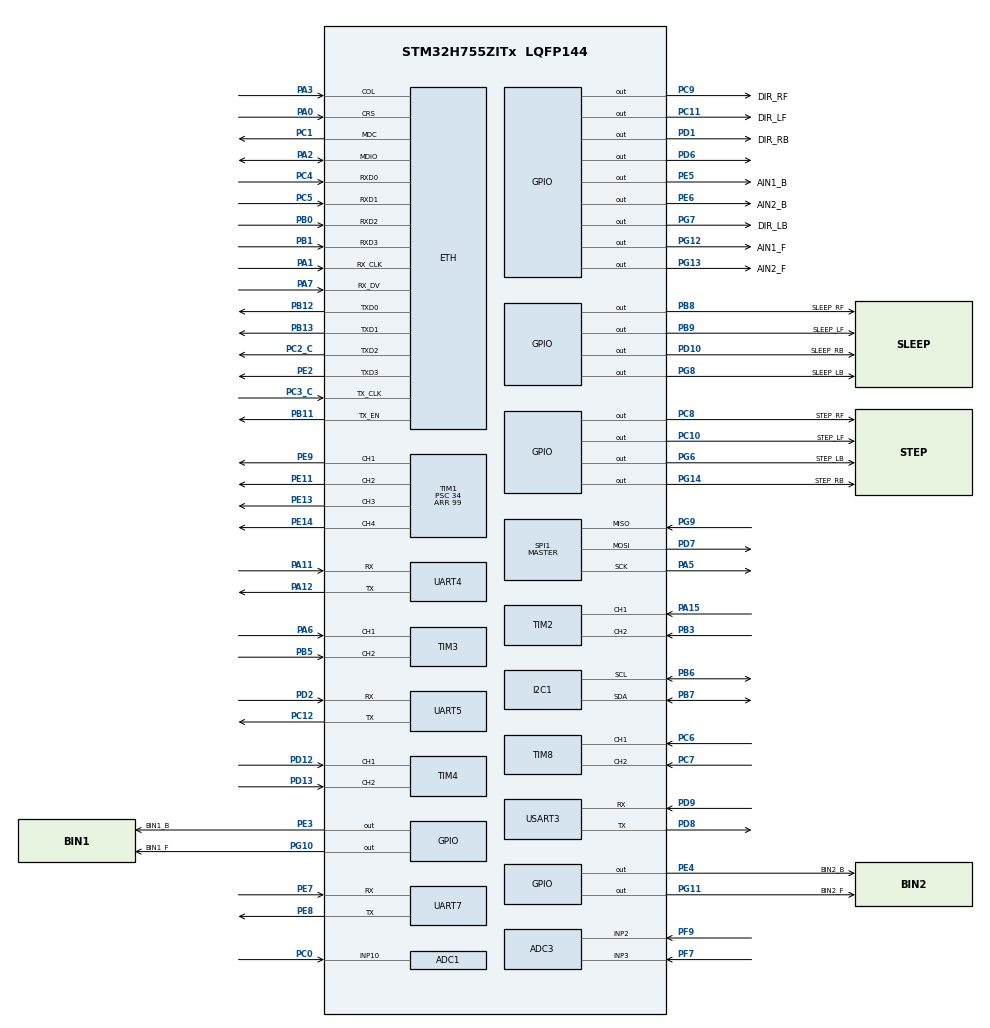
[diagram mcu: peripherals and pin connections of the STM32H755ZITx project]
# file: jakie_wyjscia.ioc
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ADC1.Channel-0\#ChannelRegularConversion=ADC_CHANNEL_10
ADC1.ClockPrescaler=ADC_CLOCK_ASYNC_DIV4
ADC1.NbrOfConversionFlag=1
ADC1.OffsetNumber-0\#ChannelRegularConversion=ADC_OFFSET_NONE
ADC1.OffsetSignedSaturation-0\#ChannelRegularConversion=DISABLE
ADC1.Rank-0\#ChannelRegularConversion=1
ADC1.SamplingTime-0\#ChannelRegularConversion=ADC_SAMPLETIME_1CYCLE_5
ADC1.master=1
ADC3.Channel-0\#ChannelRegularConversion=ADC_CHANNEL_2
ADC3.ClockPrescaler=ADC_CLOCK_ASYNC_DIV4
ADC3.NbrOfConversionFlag=1
ADC3.OffsetNumber-0\#ChannelRegularConversion=ADC_OFFSET_NONE
ADC3.OffsetSignedSaturation-0\#ChannelRegularConversion=DISABLE
ADC3.Rank-0\#ChannelRegularConversion=1
ADC3.SamplingTime-0\#ChannelRegularConversion=ADC_SAMPLETIME_1CYCLE_5
CORTEX_M7.default_mode_Activation=1
CortexM4.IPs=BDMA,CORTEX_M4\:I,DMA,FATFS_M4\:I,FREERTOS_M4\:I,GPIO,IWDG2\:I,MDMA,NVIC2\:I,OPENAMP_M4\:I,PDM2PCM_M4\:I,PWR,RCC,RESMGR_UTILITY,SYS_M4\:I,USB_DEVICE_M4\:I,USB_HOST_M4\:I,VREFBUF,WWDG2\:I
CortexM7.IPs=BDMA\:I,CORTEX_M7\:I,DMA\:I,FATFS_M7\:I,FREERTOS_M7\:I,GPIO\:I,IWDG1\:I,MDMA\:I,NVIC1\:I,OPENAMP_M7\:I,PDM2PCM_M7\:I,PWR\:I,RCC\:I,RESMGR_UTILITY\:I,SYS\:I,USB_DEVICE_M7\:I,USB_HOST_M7\:I,VREFBUF\:I,WWDG1\:I,MEMORYMAP\:I,ETH\:I,LWIP\:I,TIM1\:I,TIM2\:I,TIM3\:I,TIM4\:I,TIM8\:I,ADC3\:I,ADC1\:I,SPI1\:I,UART4\:I,DAC1\:I,ADC2\:I,TIM6\:I,TIM7\:I,UART7\:I,I2C1\:I,TIM13\:I,TIM14\:I,UART5\:I,USART3\:I,TIM15\:I
CortexM7.Pins=PE3,PE4,PE5,PE6,PD10,PG6,PG7,PG8,PC8,PC9,PC10,PC11,PD1,PD6,PG10,PG11,PG12,PG13,PG14,PB8,PB9
ETH.MediaInterface=HAL_ETH_MII_MODE
I2C1.Timing=0x00707CBB
LWIP.Version=v2.1.2_Cube
Mcu.Family=STM32H7
Mcu.Name=STM32H755ZITx
Mcu.Package=LQFP144
NVIC1.PriorityGroup=NVIC_PRIORITYGROUP_4
NVIC1.TIM15_IRQn=true\:0\:0\:false\:false\:true\:true\:true\:true
NVIC1.TIM2_IRQn=true\:0\:0\:false\:false\:true\:true\:true\:true
NVIC1.TIM6_DAC_IRQn=true\:0\:0\:false\:false\:true\:true\:true\:true
NVIC1.TIM7_IRQn=true\:0\:0\:false\:false\:true\:true\:true\:true
NVIC1.TIM8_TRG_COM_TIM14_IRQn=true\:0\:0\:false\:false\:true\:true\:true\:true
NVIC1.TIM8_UP_TIM13_IRQn=true\:0\:0\:false\:false\:true\:true\:true\:true
NVIC1.USART3_IRQn=true\:0\:0\:false\:false\:true\:true\:true\:true
NVIC2.PriorityGroup=NVIC_PRIORITYGROUP_4
PA0.Mode=MII
PA0.PinAttribute=CortexM7
PA0.Signal=ETH_CRS
PA1.Mode=MII
PA1.PinAttribute=CortexM7
PA1.Signal=ETH_RX_CLK
PA11.Mode=Asynchronous
PA11.PinAttribute=CortexM7
PA11.Signal=UART4_RX
PA12.Mode=Asynchronous
PA12.PinAttribute=CortexM7
PA12.Signal=UART4_TX
PA15\ (JTDI).PinAttribute=CortexM7
PA15\ (JTDI).Signal=S_TIM2_CH1_ETR
PA2.Mode=MII
PA2.PinAttribute=CortexM7
PA2.Signal=ETH_MDIO
PA3.Mode=MII
PA3.PinAttribute=CortexM7
PA3.Signal=ETH_COL
PA5.Mode=Full_Duplex_Master
PA5.PinAttribute=CortexM7
PA5.Signal=SPI1_SCK
PA6.PinAttribute=CortexM7
PA6.Signal=S_TIM3_CH1
PA7.Mode=MII
PA7.PinAttribute=CortexM7
PA7.Signal=ETH_RX_DV
PB0.Mode=MII
PB0.PinAttribute=CortexM7
PB0.Signal=ETH_RXD2
PB1.Mode=MII
PB1.PinAttribute=CortexM7
PB1.Signal=ETH_RXD3
PB11.Mode=MII
PB11.PinAttribute=CortexM7
PB11.Signal=ETH_TX_EN
PB12.Mode=MII
PB12.PinAttribute=CortexM7
PB12.Signal=ETH_TXD0
PB13.Mode=MII
PB13.PinAttribute=CortexM7
PB13.Signal=ETH_TXD1
PB3\ (JTDO/TRACESWO).PinAttribute=CortexM7
PB3\ (JTDO/TRACESWO).Signal=S_TIM2_CH2
PB5.PinAttribute=CortexM7
PB5.Signal=S_TIM3_CH2
PB6.Mode=I2C
PB6.PinAttribute=CortexM7
PB6.Signal=I2C1_SCL
PB7.Mode=I2C
PB7.PinAttribute=CortexM7
PB7.Signal=I2C1_SDA
PB8.GPIO_FM8=__NULL
PB8.GPIO_Label=SLEEP_RF
PB8.PinAttribute=CortexM7
PB8.Signal=GPIO_Output
PB9.GPIO_FM9=__NULL
PB9.GPIO_Label=SLEEP_LF
PB9.PinAttribute=CortexM7
PB9.Signal=GPIO_Output
PC0.PinAttribute=CortexM7
PC0.Signal=ADCx_INP10
PC1.Mode=MII
PC1.PinAttribute=CortexM7
PC1.Signal=ETH_MDC
PC10.GPIO_Label=STEP_LF
PC10.PinAttribute=CortexM7
PC10.Signal=GPIO_Output
PC11.GPIO_Label=DIR_LF
PC11.PinAttribute=CortexM7
PC11.Signal=GPIO_Output
PC12.Mode=Asynchronous
PC12.PinAttribute=CortexM7
PC12.Signal=UART5_TX
PC2_C.Mode=MII
PC2_C.PinAttribute=CortexM7
PC2_C.Signal=ETH_TXD2
PC3_C.Mode=MII
PC3_C.PinAttribute=CortexM7
PC3_C.Signal=ETH_TX_CLK
PC4.Mode=MII
PC4.PinAttribute=CortexM7
PC4.Signal=ETH_RXD0
PC5.Mode=MII
PC5.PinAttribute=CortexM7
PC5.Signal=ETH_RXD1
PC6.PinAttribute=CortexM7
PC6.Signal=S_TIM8_CH1
PC7.PinAttribute=CortexM7
PC7.Signal=S_TIM8_CH2
PC8.GPIO_Label=STEP_RF
PC8.PinAttribute=CortexM7
PC8.Signal=GPIO_Output
PC9.GPIO_Label=DIR_RF
PC9.PinAttribute=CortexM7
PC9.Signal=GPIO_Output
PD1.GPIO_Label=DIR_RB
PD1.PinAttribute=CortexM7
PD1.Signal=GPIO_Output
PD10.GPIO_Label=SLEEP_RB
PD10.PinAttribute=CortexM7
PD10.Signal=GPIO_Output
PD12.PinAttribute=CortexM7
PD12.Signal=S_TIM4_CH1
PD13.PinAttribute=CortexM7
PD13.Signal=S_TIM4_CH2
PD2.Mode=Asynchronous
PD2.PinAttribute=CortexM7
PD2.Signal=UART5_RX
PD6.PinAttribute=CortexM7
PD6.Signal=GPIO_Output
PD7.Mode=Full_Duplex_Master
PD7.PinAttribute=CortexM7
PD7.Signal=SPI1_MOSI
PD8.Mode=Asynchronous
PD8.PinAttribute=CortexM7
PD8.Signal=USART3_TX
PD9.Mode=Asynchronous
PD9.PinAttribute=CortexM7
PD9.Signal=USART3_RX
PE11.PinAttribute=CortexM7
PE11.Signal=S_TIM1_CH2
PE13.PinAttribute=CortexM7
PE13.Signal=S_TIM1_CH3
PE14.PinAttribute=CortexM7
PE14.Signal=S_TIM1_CH4
PE2.Mode=MII
PE2.PinAttribute=CortexM7
PE2.Signal=ETH_TXD3
PE3.GPIO_Label=BIN1_B
PE3.PinAttribute=CortexM7
PE3.Signal=GPIO_Output
PE4.GPIO_Label=BIN2_B
PE4.PinAttribute=CortexM7
PE4.Signal=GPIO_Output
PE5.GPIO_Label=AIN1_B
PE5.PinAttribute=CortexM7
PE5.Signal=GPIO_Output
PE6.GPIO_Label=AIN2_B
PE6.PinAttribute=CortexM7
PE6.Signal=GPIO_Output
PE7.Mode=Asynchronous
PE7.PinAttribute=CortexM7
PE7.Signal=UART7_RX
PE8.Mode=Asynchronous
PE8.PinAttribute=CortexM7
PE8.Signal=UART7_TX
PE9.PinAttribute=CortexM7
PE9.Signal=S_TIM1_CH1
PF7.Mode=IN3-Single-Ended
PF7.PinAttribute=CortexM7
PF7.Signal=ADC3_INP3
PF9.Mode=IN2-Single-Ended
PF9.PinAttribute=CortexM7
PF9.Signal=ADC3_INP2
PG10.GPIO_Label=BIN1_F
PG10.PinAttribute=CortexM7
PG10.Signal=GPIO_Output
PG11.GPIO_Label=BIN2_F
PG11.PinAttribute=CortexM7
PG11.Signal=GPIO_Output
PG12.GPIO_Label=AIN1_F
PG12.PinAttribute=CortexM7
PG12.Signal=GPIO_Output
PG13.GPIO_Label=AIN2_F
PG13.PinAttribute=CortexM7
PG13.Signal=GPIO_Output
PG14.GPIO_Label=STEP_RB
PG14.PinAttribute=CortexM7
PG14.Signal=GPIO_Output
PG6.GPIO_Label=STEP_LB
PG6.PinAttribute=CortexM7
PG6.Signal=GPIO_Output
PG7.GPIO_Label=DIR_LB
PG7.PinAttribute=CortexM7
PG7.Signal=GPIO_Output
PG8.GPIO_Label=SLEEP_LB
PG8.PinAttribute=CortexM7
PG8.Signal=GPIO_Output
PG9.Mode=Full_Duplex_Master
PG9.PinAttribute=CortexM7
PG9.Signal=SPI1_MISO
ProjectManager.HeapSize=M4-0x200,M7-0x200
ProjectManager.StackSize=M4-0x400,M7-0x400
ProjectManager.TargetToolchain=STM32CubeIDE
RCC.ADCFreq_Value=72000000
RCC.APB1Freq_Value=32000000
RCC.APB2Freq_Value=32000000
RCC.APB3Freq_Value=32000000
RCC.APB4Freq_Value=32000000
RCC.CortexFreq_Value=128000000
RCC.D1PPRE=RCC_APB3_DIV2
RCC.D2PPRE1=RCC_APB1_DIV2
RCC.D2PPRE2=RCC_APB2_DIV2
RCC.D3PPRE=RCC_APB4_DIV2
RCC.DIVM1=4
RCC.DIVM2=4
RCC.DIVN1=16
RCC.DIVN2=9
RCC.DIVQ1=3
RCC.FLatency-AdvancedSettings=FLASH_LATENCY_0
RCC.HCLKFreq_Value=64000000
RCC.HPRE=RCC_HCLK_DIV2
RCC.PLL1_VCI_Range-AdvancedSettings=RCC_PLL1VCIRANGE_0
RCC.PLL2FRACN=0
RCC.PLL2_VCI_Range-AdvancedSettings=RCC_PLL2VCIRANGE_0
RCC.PLL2_VCO_SEL-AdvancedSettings=RCC_PLL2VCOMEDIUM
RCC.PLL3FRACN=0
RCC.PLL3_VCI_Range-AdvancedSettings=RCC_PLL3VCIRANGE_0
RCC.PLL3_VCO_SEL-AdvancedSettings=RCC_PLL3VCOMEDIUM
RCC.PLLFRACN=0
RCC.SYSCLKFreq_VALUE=128000000
RCC.SYSCLKSource=RCC_SYSCLKSOURCE_PLLCLK
RCC.USBFreq_Value=85333333.33333333
SH.ADCx_INP10.0=ADC1_INP10,IN10-Single-Ended
SH.S_TIM1_CH1.0=TIM1_CH1,PWM Generation1 CH1
SH.S_TIM1_CH2.0=TIM1_CH2,PWM Generation2 CH2
SH.S_TIM1_CH3.0=TIM1_CH3,PWM Generation3 CH3
SH.S_TIM1_CH4.0=TIM1_CH4,PWM Generation4 CH4
SH.S_TIM2_CH1_ETR.0=TIM2_CH1,Encoder_Interface
SH.S_TIM2_CH2.0=TIM2_CH2,Encoder_Interface
SH.S_TIM3_CH1.0=TIM3_CH1,Encoder_Interface
SH.S_TIM3_CH2.0=TIM3_CH2,Encoder_Interface
SH.S_TIM4_CH1.0=TIM4_CH1,Encoder_Interface
SH.S_TIM4_CH2.0=TIM4_CH2,Encoder_Interface
SH.S_TIM8_CH1.0=TIM8_CH1,Encoder_Interface
SH.S_TIM8_CH2.0=TIM8_CH2,Encoder_Interface
SPI1.BaudRatePrescaler=SPI_BAUDRATEPRESCALER_2
SPI1.CalculateBaudRate=42.666664 MBits/s
SPI1.Direction=SPI_DIRECTION_2LINES
SPI1.Mode=SPI_MODE_MASTER
SPI1.VirtualType=VM_MASTER
SYS.userName=SYS_M7
TIM1.Channel-PWM\ Generation1\ CH1=TIM_CHANNEL_1
TIM1.Channel-PWM\ Generation2\ CH2=TIM_CHANNEL_2
TIM1.Channel-PWM\ Generation3\ CH3=TIM_CHANNEL_3
TIM1.Channel-PWM\ Generation4\ CH4=TIM_CHANNEL_4
TIM1.Period=99
TIM1.Prescaler=34
TIM13.Period=99
TIM13.Prescaler=6399
TIM14.Period=999
TIM14.Prescaler=39
TIM15.Period=999
TIM15.Prescaler=39
TIM2.EncoderMode=TIM_ENCODERMODE_TI12
TIM3.EncoderMode=TIM_ENCODERMODE_TI12
TIM4.EncoderMode=TIM_ENCODERMODE_TI12
TIM6.Period=999
TIM6.Prescaler=39
TIM7.Period=999
TIM7.Prescaler=39
TIM8.EncoderMode=TIM_ENCODERMODE_TI12
USART3.VirtualMode-Asynchronous=VM_ASYNC
VP_LWIP_VS_Enabled.Mode=Enabled
VP_MEMORYMAP_VS_MEMORYMAP.Mode=CurAppReg
VP_SYS_M4_VS_Systick.Mode=SysTick
VP_TIM13_VS_ClockSourceINT.Mode=Enable_Timer
VP_TIM14_VS_ClockSourceINT.Mode=Enable_Timer
VP_TIM15_VS_ClockSourceINT.Mode=Internal
VP_TIM6_VS_ClockSourceINT.Mode=Enable_Timer
VP_TIM7_VS_ClockSourceINT.Mode=Enable_Timer
board=custom

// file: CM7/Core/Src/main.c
/* USER CODE BEGIN Header */
/**
  ******************************************************************************
  * @file           : main.c
  * @brief          : Main program body
  ******************************************************************************
  * @attention
  *
  * Copyright (c) 2026 STMicroelectronics.
  * All rights reserved.
  *
  * This software is licensed under terms that can be found in the LICENSE file
  * in the root directory of this software component.
  * If no LICENSE file comes with this software, it is provided AS-IS.
  *
  ******************************************************************************
  */
/* USER CODE END Header */
#include "main.h"
#include "lwip.h"

/* USER CODE BEGIN Includes */
#include "motor_control.h"
#include "PI.h"
#include <stdbool.h>
#include <stdio.h>
#include <string.h>
#include <math.h>
/* USER CODE END Includes */

/* USER CODE BEGIN PD */

#ifndef HSEM_ID_0
#define HSEM_ID_0 (0U) /* HW semaphore 0*/
#endif

/* USER CODE END PD */

ADC_HandleTypeDef hadc1;
ADC_HandleTypeDef hadc3;

I2C_HandleTypeDef hi2c1;

SPI_HandleTypeDef hspi1;

TIM_HandleTypeDef htim1;
TIM_HandleTypeDef htim2;
TIM_HandleTypeDef htim3;
TIM_HandleTypeDef htim4;
TIM_HandleTypeDef htim6;
TIM_HandleTypeDef htim7;
TIM_HandleTypeDef htim8;
TIM_HandleTypeDef htim13;
TIM_HandleTypeDef htim14;
TIM_HandleTypeDef htim15;

UART_HandleTypeDef huart4;
UART_HandleTypeDef huart5;
UART_HandleTypeDef huart7;
UART_HandleTypeDef huart3;

/* USER CODE BEGIN PV */
uint8_t rx_byte;		/* bajt z USART3 (przerwanie RX) */
char rx_buffer[50];		/* składana komenda UART aż do '\n' */
uint8_t rx_index = 0;

/* Flagi silników krokowych (1 = dany A4988 ma być aktywny przy forward/backward). */
volatile uint8_t fright = 0, fleft = 0, bright = 0, bleft = 0, stop = 0, forward = 0, backward = 0;
volatile int Rvel = 0, Lvel = 0;	/* zadanie z UART: lspeed/rspeed w % */
volatile uint16_t steps_fright = 0, steps_bright = 0, steps_fleft = 0, steps_bleft = 0;

DC_str right_front, left_front, right_back, left_back;

int Kp = 14;
int Ki = 30;
int32_t MAX_SPEED_RPM = 200;

float P = 0;
volatile uint32_t raw_adc_val1 = 0;
volatile uint32_t raw_adc_val3 = 0;
volatile float PomiarADC;	/* prąd z przetwornika LTS (skalowanie w pętli głównej) */

/* USER CODE END PV */

void SystemClock_Config(void);
void PeriphCommonClock_Config(void);
static void MPU_Config(void);
static void MX_GPIO_Init(void);
static void MX_ADC1_Init(void);
static void MX_ADC3_Init(void);
static void MX_SPI1_Init(void);
static void MX_TIM1_Init(void);
static void MX_TIM2_Init(void);
static void MX_TIM3_Init(void);
static void MX_TIM4_Init(void);
static void MX_TIM8_Init(void);
static void MX_UART4_Init(void);
static void MX_TIM6_Init(void);
static void MX_TIM7_Init(void);
static void MX_UART7_Init(void);
static void MX_I2C1_Init(void);
static void MX_TIM13_Init(void);
static void MX_TIM14_Init(void);
static void MX_UART5_Init(void);
static void MX_USART3_UART_Init(void);
static void MX_TIM15_Init(void);

/* USER CODE BEGIN 0 */
void DC_str_init(DC_str *m, TIM_HandleTypeDef *tim, int8_t d, int32_t max)
{
	m->timer = tim;
	m->pulse_count = 0;
	m->actual_speed = 0;
	m->d = d;			/* znak enkodera — lewa/prawa oś mogą być lustrzane */
	m->max_speed = max;
	m->target_speed = 0;
	m->error_sum = 0;
	m->last_output = 0;
	m->current_setpoint = 0.0f;
	m->alpha = 0.1f;		/* silne wygładzenie na starcie */
	m->filtered_speed = 0.0f;
}

/* Telemetria: zadanie i pomiar [RPM] dla 4 kół, kolejność RB, RF, LB, LF. */
void UART_SendSpeeds(void)
{
	char msg[100];
	int len = sprintf(msg, "%ld, %ld, %ld, %ld, %ld, %ld, %ld, %ld\r\n",
			  (long)right_back.target_speed,
			  (long)right_back.filtered_speed,
			  (long)right_front.target_speed,
			  (long)right_front.filtered_speed,
			  (long)left_back.target_speed,
			  (long)left_back.filtered_speed,
			  (long)left_front.target_speed,
			  (long)left_front.filtered_speed);
	HAL_UART_Transmit(&huart3, (uint8_t *)msg, len, 10);	/* UART3 → Jetson / PC */
}

static int buzzer_tick = 0;

void HAL_TIM_PeriodElapsedCallback(TIM_HandleTypeDef *htim)
{
	/* TIM13: pętla 10 ms — buzzer po "ready", PI i PWM kół DC. */
	if (htim->Instance == TIM13) {
		/* Krótki impuls buzzera (~0,5 s) po starcie pętli regulacji. */
		if (buzzer_tick < 50) {
			HAL_GPIO_WritePin(GPIOD, GPIO_PIN_6, GPIO_PIN_SET);
			buzzer_tick++;
		} else if (buzzer_tick < 60) {
			HAL_GPIO_WritePin(GPIOD, GPIO_PIN_6, GPIO_PIN_RESET);
			buzzer_tick = 100;
		}

		DC_update_speed(&right_front);
		DC_update_speed(&left_front);
		DC_update_speed(&right_back);
		DC_update_speed(&left_back);

		static uint8_t uart_div = 0;
		if (++uart_div >= 10) {		/* 10 × 10 ms = 100 ms telemetrii */
			UART_SendSpeeds();
			uart_div = 0;
		}

		int16_t out_rf = PI_Compute(&right_front);
		int16_t out_rb = PI_Compute(&right_back);
		int16_t out_lf = PI_Compute(&left_front);
		int16_t out_lb = PI_Compute(&left_back);

		/* Skalowanie wyjścia PI do zakresu PWM mostka (0…100). */
		fright_motor(((float)out_rf / right_front.max_speed) * 100);
		bright_motor(((float)out_rb / right_back.max_speed) * 100);
		fleft_motor(((float)out_lf / left_front.max_speed) * 100);
		bleft_motor(((float)out_lb / left_back.max_speed) * 100);
	}

	/* TIM6/7/14/15: impuls STEP na A4988 + zliczanie kroków. */
	if (htim->Instance == TIM6) {
		HAL_GPIO_TogglePin(GPIOG, GPIO_PIN_6);
		if (forward) {
			steps_bleft++;
		} else {
			steps_bleft--;
		}
	}
	if (htim->Instance == TIM7) {
		HAL_GPIO_TogglePin(GPIOG, GPIO_PIN_14);
		if (forward) {
			steps_bright++;
		} else {
			steps_bright--;
		}
	}
	if (htim->Instance == TIM15) {
		HAL_GPIO_TogglePin(GPIOC, GPIO_PIN_8);
		if (forward) {
			steps_fright++;
		} else {
			steps_fright--;
		}
	}
	if (htim->Instance == TIM14) {
		HAL_GPIO_TogglePin(GPIOC, GPIO_PIN_10);
		if (forward) {
			steps_fleft++;
		} else {
			steps_fleft--;
		}
	}
}

void parse_command(char command[50])
{
	static bool ready = false;

	/* Bez "ready" pętla PI nie startuje — zabezpieczenie przed jazdą tuż po resecie USB. */
	if (strcmp(command, "ready") == 0) {
		HAL_TIM_Base_Start_IT(&htim13);
		ready = true;
	}

	if (ready) {
		/* *_step przełącza, czy dany silnik krokowy ma jechać przy forward/backward. */
		if (strcmp(command, "fright_step") == 0) {
			fright = !fright;
		} else if (strcmp(command, "fleft_step") == 0) {
			fleft = !fleft;
		} else if (strcmp(command, "bleft_step") == 0) {
			bleft = !bleft;
		} else if (strcmp(command, "bright_step") == 0) {
			bright = !bright;
		}

		if (strcmp(command, "forward") == 0) {
			stepper_control(bleft, GPIOG, GPIO_PIN_7, 1, &htim6, GPIOG, GPIO_PIN_8);
			stepper_control(bright, GPIOD, GPIO_PIN_1, 1, &htim7, GPIOD, GPIO_PIN_10);
			stepper_control(fright, GPIOC, GPIO_PIN_9, 1, &htim15, GPIOB, GPIO_PIN_8);
			stepper_control(fleft, GPIOC, GPIO_PIN_11, 1, &htim14, GPIOB, GPIO_PIN_9);
		} else if (strcmp(command, "backward") == 0) {
			stepper_control(bleft, GPIOG, GPIO_PIN_7, 0, &htim6, GPIOG, GPIO_PIN_8);
			stepper_control(bright, GPIOD, GPIO_PIN_1, 0, &htim7, GPIOD, GPIO_PIN_10);
			stepper_control(fright, GPIOC, GPIO_PIN_9, 0, &htim15, GPIOB, GPIO_PIN_8);
			stepper_control(fleft, GPIOC, GPIO_PIN_11, 0, &htim14, GPIOB, GPIO_PIN_9);
		} else if (strcmp(command, "stop") == 0) {
			stepper_control(0, GPIOG, GPIO_PIN_7, 0, &htim6, GPIOG, GPIO_PIN_8);
			stepper_control(0, GPIOD, GPIO_PIN_1, 0, &htim7, GPIOD, GPIO_PIN_10);
			stepper_control(0, GPIOC, GPIO_PIN_9, 0, &htim15, GPIOB, GPIO_PIN_8);
			stepper_control(0, GPIOC, GPIO_PIN_11, 0, &htim14, GPIOB, GPIO_PIN_9);
		}

		/* lspeed/rspeed w % max RPM, ta sama wartość na koła przednie i tylne danej burty. */
		if (strncmp(command, "lspeed=", 7) == 0) {
			if (sscanf(command, "lspeed=%d", &Lvel) == 1) {
				left_front.target_speed = (left_front.max_speed / 100) * Lvel;
				left_back.target_speed = (left_back.max_speed / 100) * Lvel;
			}
		}
		if (strncmp(command, "rspeed=", 7) == 0) {
			if (sscanf(command, "rspeed=%d", &Rvel) == 1) {
				right_front.target_speed = (right_front.max_speed / 100) * Rvel;
				right_back.target_speed = (right_back.max_speed / 100) * Rvel;
			}
		}
	}

	/* P= i I= działają też przed ready — wygodne przy strojeniu z MATLABa. */
	if (strncmp(command, "P=", 2) == 0) {
		if (sscanf(command, "P=%d", &Kp) == 1) {
			right_front.Kp = (float)Kp;
			left_front.Kp = (float)Kp;
			right_back.Kp = (float)Kp;
			left_back.Kp = (float)Kp;
		}
	}
	if (strncmp(command, "I=", 2) == 0) {
		if (sscanf(command, "I=%d", &Ki) == 1) {
			right_front.Ki = (float)Ki;
			left_front.Ki = (float)Ki;
			right_back.Ki = (float)Ki;
			left_back.Ki = (float)Ki;
		}
	}
}

/* USER CODE END 0 */

int main(void)
{

/* USER CODE BEGIN Boot_Mode_Sequence_0 */
  int32_t timeout;
/* USER CODE END Boot_Mode_Sequence_0 */

  /* MPU Configuration--------------------------------------------------------*/
  MPU_Config();

/* USER CODE BEGIN Boot_Mode_Sequence_1 */
  /* Wait until CPU2 boots and enters in stop mode or timeout*/

/* USER CODE END Boot_Mode_Sequence_1 */
  /* MCU Configuration--------------------------------------------------------*/

  /* Reset of all peripherals, Initializes the Flash interface and the Systick. */
  HAL_Init();

  /* Configure the system clock */
  SystemClock_Config();

  /* Configure the peripherals common clocks */
  PeriphCommonClock_Config();
/* USER CODE BEGIN Boot_Mode_Sequence_2 */
/* When system initialization is finished, Cortex-M7 will release Cortex-M4 by means of
HSEM notification */
/*HW semaphore Clock enable*/
__HAL_RCC_HSEM_CLK_ENABLE();
/*Take HSEM */
HAL_HSEM_FastTake(HSEM_ID_0);
/*Release HSEM in order to notify the CPU2(CM4)*/
HAL_HSEM_Release(HSEM_ID_0,0);
/* wait until CPU2 wakes up from stop mode */
timeout = 0xFFFF;
while((__HAL_RCC_GET_FLAG(RCC_FLAG_D2CKRDY) == RESET) && (timeout-- > 0));
if ( timeout < 0 )
{
Error_Handler();
}
/* USER CODE END Boot_Mode_Sequence_2 */

  /* Initialize all configured peripherals */
  MX_GPIO_Init();
  MX_ADC1_Init();
  MX_ADC3_Init();
  MX_SPI1_Init();
  MX_TIM1_Init();
  MX_TIM2_Init();
  MX_TIM3_Init();
  MX_TIM4_Init();
  MX_TIM8_Init();
  MX_UART4_Init();
  MX_LWIP_Init();
  MX_TIM6_Init();
  MX_TIM7_Init();
  MX_UART7_Init();
  MX_I2C1_Init();
  MX_TIM13_Init();
  MX_TIM14_Init();
  MX_UART5_Init();
  MX_USART3_UART_Init();
  MX_TIM15_Init();
  /* USER CODE BEGIN 2 */
  /* Osobne Kp/Ki na koło — wartości z identyfikacji (MATLAB). */
  right_front.Kp = 13; right_front.Ki =15;
  left_front.Kp  = 12; left_front.Ki = 16;
  right_back.Kp  = 10; right_back.Ki = 17;
  left_back.Kp   = 12; left_back.Ki = 16;

  /* d = -1 tam, gdzie enkoder liczy w przeciwną stronę niż zadany ruch. */
  DC_str_init(&right_front, &htim3, -1, 350);
  DC_str_init(&left_front, &htim8, -1, 350);
  DC_str_init(&right_back, &htim4, -1, 350);
  DC_str_init(&left_back, &htim2, 1, 350);

  HAL_TIM_Encoder_Start(&htim2, TIM_CHANNEL_ALL);
  HAL_TIM_Encoder_Start(&htim3, TIM_CHANNEL_ALL);
  HAL_TIM_Encoder_Start(&htim4, TIM_CHANNEL_ALL);
  HAL_TIM_Encoder_Start(&htim8, TIM_CHANNEL_ALL);

  HAL_ADCEx_Calibration_Start(&hadc1, ADC_CALIB_OFFSET, ADC_SINGLE_ENDED);
  HAL_ADCEx_Calibration_Start(&hadc3, ADC_CALIB_OFFSET, ADC_SINGLE_ENDED);

  HAL_ADC_Start(&hadc1);
  HAL_UART_Receive_IT(&huart3, &rx_byte, 1);	/* start odbioru komend z ROS */
  /* USER CODE END 2 */

  /* Infinite loop */
  /* USER CODE BEGIN WHILE */
  while (1)
  {
	  if (HAL_ADC_PollForConversion(&hadc1, 10) == HAL_OK) {
	  							/* LTS-6-NP: 16-bit ADC → prąd [A] (2 / 0.625 ze wzmocnienia). */
	  							PomiarADC = ((float)HAL_ADC_GetValue(&hadc1)/65536*3.3)*2/0.625;
	  							HAL_ADC_Start(&hadc1);
	  						}
    /* USER CODE END WHILE */

  }
}

void SystemClock_Config(void)
{
  RCC_OscInitTypeDef RCC_OscInitStruct = {0};
  RCC_ClkInitTypeDef RCC_ClkInitStruct = {0};

  /** Supply configuration update enable
  */
  HAL_PWREx_ConfigSupply(PWR_DIRECT_SMPS_SUPPLY);

  /** Configure the main internal regulator output voltage
  */
  __HAL_PWR_VOLTAGESCALING_CONFIG(PWR_REGULATOR_VOLTAGE_SCALE3);

  while(!__HAL_PWR_GET_FLAG(PWR_FLAG_VOSRDY)) {}

  /** Initializes the RCC Oscillators according to the specified parameters
  * in the RCC_OscInitTypeDef structure.
  */
  RCC_OscInitStruct.OscillatorType = RCC_OSCILLATORTYPE_HSI;
  RCC_OscInitStruct.HSIState = RCC_HSI_DIV1;
  RCC_OscInitStruct.HSICalibrationValue = RCC_HSICALIBRATION_DEFAULT;
  RCC_OscInitStruct.PLL.PLLState = RCC_PLL_ON;
  RCC_OscInitStruct.PLL.PLLSource = RCC_PLLSOURCE_HSI;
  RCC_OscInitStruct.PLL.PLLM = 4;
  RCC_OscInitStruct.PLL.PLLN = 16;
  RCC_OscInitStruct.PLL.PLLP = 2;
  RCC_OscInitStruct.PLL.PLLQ = 3;
  RCC_OscInitStruct.PLL.PLLR = 2;
  RCC_OscInitStruct.PLL.PLLRGE = RCC_PLL1VCIRANGE_3;
  RCC_OscInitStruct.PLL.PLLVCOSEL = RCC_PLL1VCOWIDE;
  RCC_OscInitStruct.PLL.PLLFRACN = 0;
  if (HAL_RCC_OscConfig(&RCC_OscInitStruct) != HAL_OK)
  {
    Error_Handler();
  }

  /** Initializes the CPU, AHB and APB buses clocks
  */
  RCC_ClkInitStruct.ClockType = RCC_CLOCKTYPE_HCLK|RCC_CLOCKTYPE_SYSCLK
                              |RCC_CLOCKTYPE_PCLK1|RCC_CLOCKTYPE_PCLK2
                              |RCC_CLOCKTYPE_D3PCLK1|RCC_CLOCKTYPE_D1PCLK1;
  RCC_ClkInitStruct.SYSCLKSource = RCC_SYSCLKSOURCE_PLLCLK;
  RCC_ClkInitStruct.SYSCLKDivider = RCC_SYSCLK_DIV1;
  RCC_ClkInitStruct.AHBCLKDivider = RCC_HCLK_DIV2;
  RCC_ClkInitStruct.APB3CLKDivider = RCC_APB3_DIV2;
  RCC_ClkInitStruct.APB1CLKDivider = RCC_APB1_DIV2;
  RCC_ClkInitStruct.APB2CLKDivider = RCC_APB2_DIV2;
  RCC_ClkInitStruct.APB4CLKDivider = RCC_APB4_DIV2;

  if (HAL_RCC_ClockConfig(&RCC_ClkInitStruct, FLASH_LATENCY_1) != HAL_OK)
  {
    Error_Handler();
  }
}

void PeriphCommonClock_Config(void)
{
  RCC_PeriphCLKInitTypeDef PeriphClkInitStruct = {0};

  /** Initializes the peripherals clock
  */
  PeriphClkInitStruct.PeriphClockSelection = RCC_PERIPHCLK_ADC;
  PeriphClkInitStruct.PLL2.PLL2M = 4;
  PeriphClkInitStruct.PLL2.PLL2N = 9;
  PeriphClkInitStruct.PLL2.PLL2P = 2;
  PeriphClkInitStruct.PLL2.PLL2Q = 2;
  PeriphClkInitStruct.PLL2.PLL2R = 2;
  PeriphClkInitStruct.PLL2.PLL2RGE = RCC_PLL2VCIRANGE_3;
  PeriphClkInitStruct.PLL2.PLL2VCOSEL = RCC_PLL2VCOWIDE;
  PeriphClkInitStruct.PLL2.PLL2FRACN = 0;
  PeriphClkInitStruct.AdcClockSelection = RCC_ADCCLKSOURCE_PLL2;
  if (HAL_RCCEx_PeriphCLKConfig(&PeriphClkInitStruct) != HAL_OK)
  {
    Error_Handler();
  }
}

static void MX_ADC1_Init(void)
{

  ADC_MultiModeTypeDef multimode = {0};
  ADC_ChannelConfTypeDef sConfig = {0};

  /** Common config
  */
  hadc1.Instance = ADC1;
  hadc1.Init.ClockPrescaler = ADC_CLOCK_ASYNC_DIV4;
  hadc1.Init.Resolution = ADC_RESOLUTION_16B;
  hadc1.Init.ScanConvMode = ADC_SCAN_DISABLE;
  hadc1.Init.EOCSelection = ADC_EOC_SINGLE_CONV;
  hadc1.Init.LowPowerAutoWait = DISABLE;
  hadc1.Init.ContinuousConvMode = DISABLE;
  hadc1.Init.NbrOfConversion = 1;
  hadc1.Init.DiscontinuousConvMode = DISABLE;
  hadc1.Init.ExternalTrigConv = ADC_SOFTWARE_START;
  hadc1.Init.ExternalTrigConvEdge = ADC_EXTERNALTRIGCONVEDGE_NONE;
  hadc1.Init.ConversionDataManagement = ADC_CONVERSIONDATA_DR;
  hadc1.Init.Overrun = ADC_OVR_DATA_PRESERVED;
  hadc1.Init.LeftBitShift = ADC_LEFTBITSHIFT_NONE;
  hadc1.Init.OversamplingMode = DISABLE;
  hadc1.Init.Oversampling.Ratio = 1;
  if (HAL_ADC_Init(&hadc1) != HAL_OK)
  {
    Error_Handler();
  }

  /** Configure the ADC multi-mode
  */
  multimode.Mode = ADC_MODE_INDEPENDENT;
  if (HAL_ADCEx_MultiModeConfigChannel(&hadc1, &multimode) != HAL_OK)
  {
    Error_Handler();
  }

  /** Configure Regular Channel
  */
  sConfig.Channel = ADC_CHANNEL_10;
  sConfig.Rank = ADC_REGULAR_RANK_1;
  sConfig.SamplingTime = ADC_SAMPLETIME_1CYCLE_5;
  sConfig.SingleDiff = ADC_SINGLE_ENDED;
  sConfig.OffsetNumber = ADC_OFFSET_NONE;
  sConfig.Offset = 0;
  sConfig.OffsetSignedSaturation = DISABLE;
  if (HAL_ADC_ConfigChannel(&hadc1, &sConfig) != HAL_OK)
  {
    Error_Handler();
  }

}

static void MX_ADC3_Init(void)
{

  ADC_ChannelConfTypeDef sConfig = {0};

  /** Common config
  */
  hadc3.Instance = ADC3;
  hadc3.Init.ClockPrescaler = ADC_CLOCK_ASYNC_DIV4;
  hadc3.Init.Resolution = ADC_RESOLUTION_16B;
  hadc3.Init.ScanConvMode = ADC_SCAN_DISABLE;
  hadc3.Init.EOCSelection = ADC_EOC_SINGLE_CONV;
  hadc3.Init.LowPowerAutoWait = DISABLE;
  hadc3.Init.ContinuousConvMode = DISABLE;
  hadc3.Init.NbrOfConversion = 1;
  hadc3.Init.DiscontinuousConvMode = DISABLE;
  hadc3.Init.ExternalTrigConv = ADC_SOFTWARE_START;
  hadc3.Init.ExternalTrigConvEdge = ADC_EXTERNALTRIGCONVEDGE_NONE;
  hadc3.Init.ConversionDataManagement = ADC_CONVERSIONDATA_DR;
  hadc3.Init.Overrun = ADC_OVR_DATA_PRESERVED;
  hadc3.Init.LeftBitShift = ADC_LEFTBITSHIFT_NONE;
  hadc3.Init.OversamplingMode = DISABLE;
  hadc3.Init.Oversampling.Ratio = 1;
  if (HAL_ADC_Init(&hadc3) != HAL_OK)
  {
    Error_Handler();
  }

  /** Configure Regular Channel
  */
  sConfig.Channel = ADC_CHANNEL_2;
  sConfig.Rank = ADC_REGULAR_RANK_1;
  sConfig.SamplingTime = ADC_SAMPLETIME_1CYCLE_5;
  sConfig.SingleDiff = ADC_SINGLE_ENDED;
  sConfig.OffsetNumber = ADC_OFFSET_NONE;
  sConfig.Offset = 0;
  sConfig.OffsetSignedSaturation = DISABLE;
  if (HAL_ADC_ConfigChannel(&hadc3, &sConfig) != HAL_OK)
  {
    Error_Handler();
  }

}

static void MX_I2C1_Init(void)
{

  hi2c1.Instance = I2C1;
  hi2c1.Init.Timing = 0x00707CBB;
  hi2c1.Init.OwnAddress1 = 0;
  hi2c1.Init.AddressingMode = I2C_ADDRESSINGMODE_7BIT;
  hi2c1.Init.DualAddressMode = I2C_DUALADDRESS_DISABLE;
  hi2c1.Init.OwnAddress2 = 0;
  hi2c1.Init.OwnAddress2Masks = I2C_OA2_NOMASK;
  hi2c1.Init.GeneralCallMode = I2C_GENERALCALL_DISABLE;
  hi2c1.Init.NoStretchMode = I2C_NOSTRETCH_DISABLE;
  if (HAL_I2C_Init(&hi2c1) != HAL_OK)
  {
    Error_Handler();
  }

  /** Configure Analogue filter
  */
  if (HAL_I2CEx_ConfigAnalogFilter(&hi2c1, I2C_ANALOGFILTER_ENABLE) != HAL_OK)
  {
    Error_Handler();
  }

  /** Configure Digital filter
  */
  if (HAL_I2CEx_ConfigDigitalFilter(&hi2c1, 0) != HAL_OK)
  {
    Error_Handler();
  }

}

static void MX_SPI1_Init(void)
{

  /* SPI1 parameter configuration*/
  hspi1.Instance = SPI1;
  hspi1.Init.Mode = SPI_MODE_MASTER;
  hspi1.Init.Direction = SPI_DIRECTION_2LINES;
  hspi1.Init.DataSize = SPI_DATASIZE_4BIT;
  hspi1.Init.CLKPolarity = SPI_POLARITY_LOW;
  hspi1.Init.CLKPhase = SPI_PHASE_1EDGE;
  hspi1.Init.NSS = SPI_NSS_SOFT;
  hspi1.Init.BaudRatePrescaler = SPI_BAUDRATEPRESCALER_2;
  hspi1.Init.FirstBit = SPI_FIRSTBIT_MSB;
  hspi1.Init.TIMode = SPI_TIMODE_DISABLE;
  hspi1.Init.CRCCalculation = SPI_CRCCALCULATION_DISABLE;
  hspi1.Init.CRCPolynomial = 0x0;
  hspi1.Init.NSSPMode = SPI_NSS_PULSE_ENABLE;
  hspi1.Init.NSSPolarity = SPI_NSS_POLARITY_LOW;
  hspi1.Init.FifoThreshold = SPI_FIFO_THRESHOLD_01DATA;
  hspi1.Init.TxCRCInitializationPattern = SPI_CRC_INITIALIZATION_ALL_ZERO_PATTERN;
  hspi1.Init.RxCRCInitializationPattern = SPI_CRC_INITIALIZATION_ALL_ZERO_PATTERN;
  hspi1.Init.MasterSSIdleness = SPI_MASTER_SS_IDLENESS_00CYCLE;
  hspi1.Init.MasterInterDataIdleness = SPI_MASTER_INTERDATA_IDLENESS_00CYCLE;
  hspi1.Init.MasterReceiverAutoSusp = SPI_MASTER_RX_AUTOSUSP_DISABLE;
  hspi1.Init.MasterKeepIOState = SPI_MASTER_KEEP_IO_STATE_DISABLE;
  hspi1.Init.IOSwap = SPI_IO_SWAP_DISABLE;
  if (HAL_SPI_Init(&hspi1) != HAL_OK)
  {
    Error_Handler();
  }

}

static void MX_TIM1_Init(void)
{

  TIM_MasterConfigTypeDef sMasterConfig = {0};
  TIM_OC_InitTypeDef sConfigOC = {0};
  TIM_BreakDeadTimeConfigTypeDef sBreakDeadTimeConfig = {0};

  htim1.Instance = TIM1;
  htim1.Init.Prescaler = 34;
  htim1.Init.CounterMode = TIM_COUNTERMODE_UP;
  htim1.Init.Period = 99;
  htim1.Init.ClockDivision = TIM_CLOCKDIVISION_DIV1;
  htim1.Init.RepetitionCounter = 0;
  htim1.Init.AutoReloadPreload = TIM_AUTORELOAD_PRELOAD_DISABLE;
  if (HAL_TIM_PWM_Init(&htim1) != HAL_OK)
  {
    Error_Handler();
  }
  sMasterConfig.MasterOutputTrigger = TIM_TRGO_RESET;
  sMasterConfig.MasterOutputTrigger2 = TIM_TRGO2_RESET;
  sMasterConfig.MasterSlaveMode = TIM_MASTERSLAVEMODE_DISABLE;
  if (HAL_TIMEx_MasterConfigSynchronization(&htim1, &sMasterConfig) != HAL_OK)
  {
    Error_Handler();
  }
  sConfigOC.OCMode = TIM_OCMODE_PWM1;
  sConfigOC.Pulse = 0;
  sConfigOC.OCPolarity = TIM_OCPOLARITY_HIGH;
  sConfigOC.OCNPolarity = TIM_OCNPOLARITY_HIGH;
  sConfigOC.OCFastMode = TIM_OCFAST_DISABLE;
  sConfigOC.OCIdleState = TIM_OCIDLESTATE_RESET;
  sConfigOC.OCNIdleState = TIM_OCNIDLESTATE_RESET;
  if (HAL_TIM_PWM_ConfigChannel(&htim1, &sConfigOC, TIM_CHANNEL_1) != HAL_OK)
  {
    Error_Handler();
  }
  if (HAL_TIM_PWM_ConfigChannel(&htim1, &sConfigOC, TIM_CHANNEL_2) != HAL_OK)
  {
    Error_Handler();
  }
  if (HAL_TIM_PWM_ConfigChannel(&htim1, &sConfigOC, TIM_CHANNEL_3) != HAL_OK)
  {
    Error_Handler();
  }
  if (HAL_TIM_PWM_ConfigChannel(&htim1, &sConfigOC, TIM_CHANNEL_4) != HAL_OK)
  {
    Error_Handler();
  }
  sBreakDeadTimeConfig.OffStateRunMode = TIM_OSSR_DISABLE;
  sBreakDeadTimeConfig.OffStateIDLEMode = TIM_OSSI_DISABLE;
  sBreakDeadTimeConfig.LockLevel = TIM_LOCKLEVEL_OFF;
  sBreakDeadTimeConfig.DeadTime = 0;
  sBreakDeadTimeConfig.BreakState = TIM_BREAK_DISABLE;
  sBreakDeadTimeConfig.BreakPolarity = TIM_BREAKPOLARITY_HIGH;
  sBreakDeadTimeConfig.BreakFilter = 0;
  sBreakDeadTimeConfig.Break2State = TIM_BREAK2_DISABLE;
  sBreakDeadTimeConfig.Break2Polarity = TIM_BREAK2POLARITY_HIGH;
  sBreakDeadTimeConfig.Break2Filter = 0;
  sBreakDeadTimeConfig.AutomaticOutput = TIM_AUTOMATICOUTPUT_DISABLE;
  if (HAL_TIMEx_ConfigBreakDeadTime(&htim1, &sBreakDeadTimeConfig) != HAL_OK)
  {
    Error_Handler();
  }
  HAL_TIM_MspPostInit(&htim1);

}

static void MX_TIM2_Init(void)
{

  TIM_Encoder_InitTypeDef sConfig = {0};
  TIM_MasterConfigTypeDef sMasterConfig = {0};

  htim2.Instance = TIM2;
  htim2.Init.Prescaler = 0;
  htim2.Init.CounterMode = TIM_COUNTERMODE_UP;
  htim2.Init.Period = 4294967295;
  htim2.Init.ClockDivision = TIM_CLOCKDIVISION_DIV1;
  htim2.Init.AutoReloadPreload = TIM_AUTORELOAD_PRELOAD_DISABLE;
  sConfig.EncoderMode = TIM_ENCODERMODE_TI12;
  sConfig.IC1Polarity = TIM_ICPOLARITY_RISING;
  sConfig.IC1Selection = TIM_ICSELECTION_DIRECTTI;
  sConfig.IC1Prescaler = TIM_ICPSC_DIV1;
  sConfig.IC1Filter = 0;
  sConfig.IC2Polarity = TIM_ICPOLARITY_RISING;
  sConfig.IC2Selection = TIM_ICSELECTION_DIRECTTI;
  sConfig.IC2Prescaler = TIM_ICPSC_DIV1;
  sConfig.IC2Filter = 0;
  if (HAL_TIM_Encoder_Init(&htim2, &sConfig) != HAL_OK)
  {
    Error_Handler();
  }
  sMasterConfig.MasterOutputTrigger = TIM_TRGO_RESET;
  sMasterConfig.MasterSlaveMode = TIM_MASTERSLAVEMODE_DISABLE;
  if (HAL_TIMEx_MasterConfigSynchronization(&htim2, &sMasterConfig) != HAL_OK)
  {
    Error_Handler();
  }

}

static void MX_TIM3_Init(void)
{

  TIM_Encoder_InitTypeDef sConfig = {0};
  TIM_MasterConfigTypeDef sMasterConfig = {0};

  htim3.Instance = TIM3;
  htim3.Init.Prescaler = 0;
  htim3.Init.CounterMode = TIM_COUNTERMODE_UP;
  htim3.Init.Period = 65535;
  htim3.Init.ClockDivision = TIM_CLOCKDIVISION_DIV1;
  htim3.Init.AutoReloadPreload = TIM_AUTORELOAD_PRELOAD_DISABLE;
  sConfig.EncoderMode = TIM_ENCODERMODE_TI12;
  sConfig.IC1Polarity = TIM_ICPOLARITY_RISING;
  sConfig.IC1Selection = TIM_ICSELECTION_DIRECTTI;
  sConfig.IC1Prescaler = TIM_ICPSC_DIV1;
  sConfig.IC1Filter = 0;
  sConfig.IC2Polarity = TIM_ICPOLARITY_RISING;
  sConfig.IC2Selection = TIM_ICSELECTION_DIRECTTI;
  sConfig.IC2Prescaler = TIM_ICPSC_DIV1;
  sConfig.IC2Filter = 0;
  if (HAL_TIM_Encoder_Init(&htim3, &sConfig) != HAL_OK)
  {
    Error_Handler();
  }
  sMasterConfig.MasterOutputTrigger = TIM_TRGO_RESET;
  sMasterConfig.MasterSlaveMode = TIM_MASTERSLAVEMODE_DISABLE;
  if (HAL_TIMEx_MasterConfigSynchronization(&htim3, &sMasterConfig) != HAL_OK)
  {
    Error_Handler();
  }

}

static void MX_TIM4_Init(void)
{

  TIM_Encoder_InitTypeDef sConfig = {0};
  TIM_MasterConfigTypeDef sMasterConfig = {0};

  htim4.Instance = TIM4;
  htim4.Init.Prescaler = 0;
  htim4.Init.CounterMode = TIM_COUNTERMODE_UP;
  htim4.Init.Period = 65535;
  htim4.Init.ClockDivision = TIM_CLOCKDIVISION_DIV1;
  htim4.Init.AutoReloadPreload = TIM_AUTORELOAD_PRELOAD_DISABLE;
  sConfig.EncoderMode = TIM_ENCODERMODE_TI12;
  sConfig.IC1Polarity = TIM_ICPOLARITY_RISING;
  sConfig.IC1Selection = TIM_ICSELECTION_DIRECTTI;
  sConfig.IC1Prescaler = TIM_ICPSC_DIV1;
  sConfig.IC1Filter = 0;
  sConfig.IC2Polarity = TIM_ICPOLARITY_RISING;
  sConfig.IC2Selection = TIM_ICSELECTION_DIRECTTI;
  sConfig.IC2Prescaler = TIM_ICPSC_DIV1;
  sConfig.IC2Filter = 0;
  if (HAL_TIM_Encoder_Init(&htim4, &sConfig) != HAL_OK)
  {
    Error_Handler();
  }
  sMasterConfig.MasterOutputTrigger = TIM_TRGO_RESET;
  sMasterConfig.MasterSlaveMode = TIM_MASTERSLAVEMODE_DISABLE;
  if (HAL_TIMEx_MasterConfigSynchronization(&htim4, &sMasterConfig) != HAL_OK)
  {
    Error_Handler();
  }

}

static void MX_TIM6_Init(void)
{

  TIM_MasterConfigTypeDef sMasterConfig = {0};

  htim6.Instance = TIM6;
  htim6.Init.Prescaler = 39;
  htim6.Init.CounterMode = TIM_COUNTERMODE_UP;
  htim6.Init.Period = 999;
  htim6.Init.AutoReloadPreload = TIM_AUTORELOAD_PRELOAD_DISABLE;
  if (HAL_TIM_Base_Init(&htim6) != HAL_OK)
  {
    Error_Handler();
  }
  sMasterConfig.MasterOutputTrigger = TIM_TRGO_RESET;
  sMasterConfig.MasterSlaveMode = TIM_MASTERSLAVEMODE_DISABLE;
  if (HAL_TIMEx_MasterConfigSynchronization(&htim6, &sMasterConfig) != HAL_OK)
  {
    Error_Handler();
  }

}

static void MX_TIM7_Init(void)
{

  TIM_MasterConfigTypeDef sMasterConfig = {0};

  htim7.Instance = TIM7;
  htim7.Init.Prescaler = 39;
  htim7.Init.CounterMode = TIM_COUNTERMODE_UP;
  htim7.Init.Period = 999;
  htim7.Init.AutoReloadPreload = TIM_AUTORELOAD_PRELOAD_DISABLE;
  if (HAL_TIM_Base_Init(&htim7) != HAL_OK)
  {
    Error_Handler();
  }
  sMasterConfig.MasterOutputTrigger = TIM_TRGO_RESET;
  sMasterConfig.MasterSlaveMode = TIM_MASTERSLAVEMODE_DISABLE;
  if (HAL_TIMEx_MasterConfigSynchronization(&htim7, &sMasterConfig) != HAL_OK)
  {
    Error_Handler();
  }

}

static void MX_TIM8_Init(void)
{

  TIM_Encoder_InitTypeDef sConfig = {0};
  TIM_MasterConfigTypeDef sMasterConfig = {0};

  htim8.Instance = TIM8;
  htim8.Init.Prescaler = 0;
  htim8.Init.CounterMode = TIM_COUNTERMODE_UP;
  htim8.Init.Period = 65535;
  htim8.Init.ClockDivision = TIM_CLOCKDIVISION_DIV1;
  htim8.Init.RepetitionCounter = 0;
  htim8.Init.AutoReloadPreload = TIM_AUTORELOAD_PRELOAD_DISABLE;
  sConfig.EncoderMode = TIM_ENCODERMODE_TI12;
  sConfig.IC1Polarity = TIM_ICPOLARITY_RISING;
  sConfig.IC1Selection = TIM_ICSELECTION_DIRECTTI;
  sConfig.IC1Prescaler = TIM_ICPSC_DIV1;
  sConfig.IC1Filter = 0;
  sConfig.IC2Polarity = TIM_ICPOLARITY_RISING;
  sConfig.IC2Selection = TIM_ICSELECTION_DIRECTTI;
  sConfig.IC2Prescaler = TIM_ICPSC_DIV1;
  sConfig.IC2Filter = 0;
  if (HAL_TIM_Encoder_Init(&htim8, &sConfig) != HAL_OK)
  {
    Error_Handler();
  }
  sMasterConfig.MasterOutputTrigger = TIM_TRGO_RESET;
  sMasterConfig.MasterOutputTrigger2 = TIM_TRGO2_RESET;
  sMasterConfig.MasterSlaveMode = TIM_MASTERSLAVEMODE_DISABLE;
  if (HAL_TIMEx_MasterConfigSynchronization(&htim8, &sMasterConfig) != HAL_OK)
  {
    Error_Handler();
  }

}

static void MX_TIM13_Init(void)
{

  htim13.Instance = TIM13;
  htim13.Init.Prescaler = 6399;
  htim13.Init.CounterMode = TIM_COUNTERMODE_UP;
  htim13.Init.Period = 99;
  htim13.Init.ClockDivision = TIM_CLOCKDIVISION_DIV1;
  htim13.Init.AutoReloadPreload = TIM_AUTORELOAD_PRELOAD_DISABLE;
  if (HAL_TIM_Base_Init(&htim13) != HAL_OK)
  {
    Error_Handler();
  }

}

static void MX_TIM14_Init(void)
{

  htim14.Instance = TIM14;
  htim14.Init.Prescaler = 39;
  htim14.Init.CounterMode = TIM_COUNTERMODE_UP;
  htim14.Init.Period = 999;
  htim14.Init.ClockDivision = TIM_CLOCKDIVISION_DIV1;
  htim14.Init.AutoReloadPreload = TIM_AUTORELOAD_PRELOAD_DISABLE;
  if (HAL_TIM_Base_Init(&htim14) != HAL_OK)
  {
    Error_Handler();
  }

}

static void MX_TIM15_Init(void)
{

  TIM_ClockConfigTypeDef sClockSourceConfig = {0};
  TIM_MasterConfigTypeDef sMasterConfig = {0};

  htim15.Instance = TIM15;
  htim15.Init.Prescaler = 39;
  htim15.Init.CounterMode = TIM_COUNTERMODE_UP;
  htim15.Init.Period = 999;
  htim15.Init.ClockDivision = TIM_CLOCKDIVISION_DIV1;
  htim15.Init.RepetitionCounter = 0;
  htim15.Init.AutoReloadPreload = TIM_AUTORELOAD_PRELOAD_DISABLE;
  if (HAL_TIM_Base_Init(&htim15) != HAL_OK)
  {
    Error_Handler();
  }
  sClockSourceConfig.ClockSource = TIM_CLOCKSOURCE_INTERNAL;
  if (HAL_TIM_ConfigClockSource(&htim15, &sClockSourceConfig) != HAL_OK)
  {
    Error_Handler();
  }
  sMasterConfig.MasterOutputTrigger = TIM_TRGO_RESET;
  sMasterConfig.MasterSlaveMode = TIM_MASTERSLAVEMODE_DISABLE;
  if (HAL_TIMEx_MasterConfigSynchronization(&htim15, &sMasterConfig) != HAL_OK)
  {
    Error_Handler();
  }

}

static void MX_UART4_Init(void)
{

  huart4.Instance = UART4;
  huart4.Init.BaudRate = 115200;
  huart4.Init.WordLength = UART_WORDLENGTH_8B;
  huart4.Init.StopBits = UART_STOPBITS_1;
  huart4.Init.Parity = UART_PARITY_NONE;
  huart4.Init.Mode = UART_MODE_TX_RX;
  huart4.Init.HwFlowCtl = UART_HWCONTROL_NONE;
  huart4.Init.OverSampling = UART_OVERSAMPLING_16;
  huart4.Init.OneBitSampling = UART_ONE_BIT_SAMPLE_DISABLE;
  huart4.Init.ClockPrescaler = UART_PRESCALER_DIV1;
  huart4.AdvancedInit.AdvFeatureInit = UART_ADVFEATURE_NO_INIT;
  if (HAL_UART_Init(&huart4) != HAL_OK)
  {
    Error_Handler();
  }
  if (HAL_UARTEx_SetTxFifoThreshold(&huart4, UART_TXFIFO_THRESHOLD_1_8) != HAL_OK)
  {
    Error_Handler();
  }
  if (HAL_UARTEx_SetRxFifoThreshold(&huart4, UART_RXFIFO_THRESHOLD_1_8) != HAL_OK)
  {
    Error_Handler();
  }
  if (HAL_UARTEx_DisableFifoMode(&huart4) != HAL_OK)
  {
    Error_Handler();
  }

}

static void MX_UART5_Init(void)
{

  huart5.Instance = UART5;
  huart5.Init.BaudRate = 115200;
  huart5.Init.WordLength = UART_WORDLENGTH_8B;
  huart5.Init.StopBits = UART_STOPBITS_1;
  huart5.Init.Parity = UART_PARITY_NONE;
  huart5.Init.Mode = UART_MODE_TX_RX;
  huart5.Init.HwFlowCtl = UART_HWCONTROL_NONE;
  huart5.Init.OverSampling = UART_OVERSAMPLING_16;
  huart5.Init.OneBitSampling = UART_ONE_BIT_SAMPLE_DISABLE;
  huart5.Init.ClockPrescaler = UART_PRESCALER_DIV1;
  huart5.AdvancedInit.AdvFeatureInit = UART_ADVFEATURE_NO_INIT;
  if (HAL_UART_Init(&huart5) != HAL_OK)
  {
    Error_Handler();
  }
  if (HAL_UARTEx_SetTxFifoThreshold(&huart5, UART_TXFIFO_THRESHOLD_1_8) != HAL_OK)
  {
    Error_Handler();
  }
  if (HAL_UARTEx_SetRxFifoThreshold(&huart5, UART_RXFIFO_THRESHOLD_1_8) != HAL_OK)
  {
    Error_Handler();
  }
  if (HAL_UARTEx_DisableFifoMode(&huart5) != HAL_OK)
  {
    Error_Handler();
  }

}

static void MX_UART7_Init(void)
{

  huart7.Instance = UART7;
  huart7.Init.BaudRate = 115200;
  huart7.Init.WordLength = UART_WORDLENGTH_8B;
  huart7.Init.StopBits = UART_STOPBITS_1;
  huart7.Init.Parity = UART_PARITY_NONE;
  huart7.Init.Mode = UART_MODE_TX_RX;
  huart7.Init.HwFlowCtl = UART_HWCONTROL_NONE;
  huart7.Init.OverSampling = UART_OVERSAMPLING_16;
  huart7.Init.OneBitSampling = UART_ONE_BIT_SAMPLE_DISABLE;
  huart7.Init.ClockPrescaler = UART_PRESCALER_DIV1;
  huart7.AdvancedInit.AdvFeatureInit = UART_ADVFEATURE_NO_INIT;
  if (HAL_UART_Init(&huart7) != HAL_OK)
  {
    Error_Handler();
  }
  if (HAL_UARTEx_SetTxFifoThreshold(&huart7, UART_TXFIFO_THRESHOLD_1_8) != HAL_OK)
  {
    Error_Handler();
  }
  if (HAL_UARTEx_SetRxFifoThreshold(&huart7, UART_RXFIFO_THRESHOLD_1_8) != HAL_OK)
  {
    Error_Handler();
  }
  if (HAL_UARTEx_DisableFifoMode(&huart7) != HAL_OK)
  {
    Error_Handler();
  }

}

static void MX_USART3_UART_Init(void)
{

  huart3.Instance = USART3;
  huart3.Init.BaudRate = 115200;
  huart3.Init.WordLength = UART_WORDLENGTH_8B;
  huart3.Init.StopBits = UART_STOPBITS_1;
  huart3.Init.Parity = UART_PARITY_NONE;
  huart3.Init.Mode = UART_MODE_TX_RX;
  huart3.Init.HwFlowCtl = UART_HWCONTROL_NONE;
  huart3.Init.OverSampling = UART_OVERSAMPLING_16;
  huart3.Init.OneBitSampling = UART_ONE_BIT_SAMPLE_DISABLE;
  huart3.Init.ClockPrescaler = UART_PRESCALER_DIV1;
  huart3.AdvancedInit.AdvFeatureInit = UART_ADVFEATURE_NO_INIT;
  if (HAL_UART_Init(&huart3) != HAL_OK)
  {
    Error_Handler();
  }
  if (HAL_UARTEx_SetTxFifoThreshold(&huart3, UART_TXFIFO_THRESHOLD_1_8) != HAL_OK)
  {
    Error_Handler();
  }
  if (HAL_UARTEx_SetRxFifoThreshold(&huart3, UART_RXFIFO_THRESHOLD_1_8) != HAL_OK)
  {
    Error_Handler();
  }
  if (HAL_UARTEx_DisableFifoMode(&huart3) != HAL_OK)
  {
    Error_Handler();
  }

}

static void MX_GPIO_Init(void)
{
  GPIO_InitTypeDef GPIO_InitStruct = {0};

  /* GPIO Ports Clock Enable */
  __HAL_RCC_GPIOE_CLK_ENABLE();
  __HAL_RCC_GPIOF_CLK_ENABLE();
  __HAL_RCC_GPIOC_CLK_ENABLE();
  __HAL_RCC_GPIOA_CLK_ENABLE();
  __HAL_RCC_GPIOB_CLK_ENABLE();
  __HAL_RCC_GPIOD_CLK_ENABLE();
  __HAL_RCC_GPIOG_CLK_ENABLE();

  /*Configure GPIO pin Output Level */
  HAL_GPIO_WritePin(GPIOE, BIN1_B_Pin|BIN2_B_Pin|AIN1_B_Pin|AIN2_B_Pin, GPIO_PIN_RESET);

  /*Configure GPIO pin Output Level */
  HAL_GPIO_WritePin(GPIOD, SLEEP_RB_Pin|DIR_RB_Pin|GPIO_PIN_6, GPIO_PIN_RESET);

  /*Configure GPIO pin Output Level */
  HAL_GPIO_WritePin(GPIOG, STEP_LB_Pin|DIR_LB_Pin|SLEEP_LB_Pin|BIN1_F_Pin
                          |BIN2_F_Pin|AIN1_F_Pin|AIN2_F_Pin|STEP_RB_Pin, GPIO_PIN_RESET);

  /*Configure GPIO pin Output Level */
  HAL_GPIO_WritePin(GPIOC, STEP_RF_Pin|DIR_RF_Pin|STEP_LF_Pin|DIR_LF_Pin, GPIO_PIN_RESET);

  /*Configure GPIO pin Output Level */
  HAL_GPIO_WritePin(GPIOB, SLEEP_RF_Pin|SLEEP_LF_Pin, GPIO_PIN_RESET);

  /*Configure GPIO pins : BIN1_B_Pin BIN2_B_Pin AIN1_B_Pin AIN2_B_Pin */
  GPIO_InitStruct.Pin = BIN1_B_Pin|BIN2_B_Pin|AIN1_B_Pin|AIN2_B_Pin;
  GPIO_InitStruct.Mode = GPIO_MODE_OUTPUT_PP;
  GPIO_InitStruct.Pull = GPIO_NOPULL;
  GPIO_InitStruct.Speed = GPIO_SPEED_FREQ_LOW;
  HAL_GPIO_Init(GPIOE, &GPIO_InitStruct);

  /*Configure GPIO pins : SLEEP_RB_Pin DIR_RB_Pin PD6 */
  GPIO_InitStruct.Pin = SLEEP_RB_Pin|DIR_RB_Pin|GPIO_PIN_6;
  GPIO_InitStruct.Mode = GPIO_MODE_OUTPUT_PP;
  GPIO_InitStruct.Pull = GPIO_NOPULL;
  GPIO_InitStruct.Speed = GPIO_SPEED_FREQ_LOW;
  HAL_GPIO_Init(GPIOD, &GPIO_InitStruct);

  /*Configure GPIO pins : STEP_LB_Pin DIR_LB_Pin SLEEP_LB_Pin BIN1_F_Pin
                           BIN2_F_Pin AIN1_F_Pin AIN2_F_Pin STEP_RB_Pin */
  GPIO_InitStruct.Pin = STEP_LB_Pin|DIR_LB_Pin|SLEEP_LB_Pin|BIN1_F_Pin
                          |BIN2_F_Pin|AIN1_F_Pin|AIN2_F_Pin|STEP_RB_Pin;
  GPIO_InitStruct.Mode = GPIO_MODE_OUTPUT_PP;
  GPIO_InitStruct.Pull = GPIO_NOPULL;
  GPIO_InitStruct.Speed = GPIO_SPEED_FREQ_LOW;
  HAL_GPIO_Init(GPIOG, &GPIO_InitStruct);

  /*Configure GPIO pins : STEP_RF_Pin DIR_RF_Pin STEP_LF_Pin DIR_LF_Pin */
  GPIO_InitStruct.Pin = STEP_RF_Pin|DIR_RF_Pin|STEP_LF_Pin|DIR_LF_Pin;
  GPIO_InitStruct.Mode = GPIO_MODE_OUTPUT_PP;
  GPIO_InitStruct.Pull = GPIO_NOPULL;
  GPIO_InitStruct.Speed = GPIO_SPEED_FREQ_LOW;
  HAL_GPIO_Init(GPIOC, &GPIO_InitStruct);

  /*Configure GPIO pins : SLEEP_RF_Pin SLEEP_LF_Pin */
  GPIO_InitStruct.Pin = SLEEP_RF_Pin|SLEEP_LF_Pin;
  GPIO_InitStruct.Mode = GPIO_MODE_OUTPUT_PP;
  GPIO_InitStruct.Pull = GPIO_NOPULL;
  GPIO_InitStruct.Speed = GPIO_SPEED_FREQ_LOW;
  HAL_GPIO_Init(GPIOB, &GPIO_InitStruct);

}

/* USER CODE BEGIN 4 */
void HAL_UART_RxCpltCallback(UART_HandleTypeDef *huart)
{
	if (huart->Instance == USART3) {
		if (rx_byte == '\n' || rx_byte == '\r') {
			rx_buffer[rx_index] = 0;	/* zakończ string */
			parse_command(rx_buffer);
			rx_index = 0;
		} else if (rx_index < 49) {	/* ochrona przed przepełnieniem bufora */
			rx_buffer[rx_index++] = rx_byte;
		}
		/* RX IT trzeba zbroić ponownie po każdym bajcie. */
		HAL_UART_Receive_IT(&huart3, &rx_byte, 1);
	}
}
/* USER CODE END 4 */

 /* MPU Configuration */

void MPU_Config(void)
{
  MPU_Region_InitTypeDef MPU_InitStruct = {0};

  /* Disables the MPU */
  HAL_MPU_Disable();

  /** Initializes and configures the Region and the memory to be protected
  */
  MPU_InitStruct.Enable = MPU_REGION_ENABLE;
  MPU_InitStruct.Number = MPU_REGION_NUMBER0;
  MPU_InitStruct.BaseAddress = 0x0;
  MPU_InitStruct.Size = MPU_REGION_SIZE_4GB;
  MPU_InitStruct.SubRegionDisable = 0x87;
  MPU_InitStruct.TypeExtField = MPU_TEX_LEVEL0;
  MPU_InitStruct.AccessPermission = MPU_REGION_NO_ACCESS;
  MPU_InitStruct.DisableExec = MPU_INSTRUCTION_ACCESS_DISABLE;
  MPU_InitStruct.IsShareable = MPU_ACCESS_SHAREABLE;
  MPU_InitStruct.IsCacheable = MPU_ACCESS_NOT_CACHEABLE;
  MPU_InitStruct.IsBufferable = MPU_ACCESS_NOT_BUFFERABLE;

  HAL_MPU_ConfigRegion(&MPU_InitStruct);
  /* Enables the MPU */
  HAL_MPU_Enable(MPU_PRIVILEGED_DEFAULT);

}

void Error_Handler(void)
{
  __disable_irq();
  while (1)
  {
  }
}
